# LPC55S66_cm33_core1 register map
Vendor: nxp.com; File version: 1.0
CPU: CM33 r2p0, little endian, no MPU, no FPU, VTOR, 3 interrupt priority bits
Registers are 32-bit, read-write, reset 0x0 unless marked. A register's access mark holds for its fields unless they carry their own. Offsets are from the block's base; [hi:lo] are bit positions; {n}, {i} and the like mark numbered series; 'fields as' and 'values as' point back to an identical list.

## IOCON — I/O pin configuration (IOCON)
Base 0x40001000
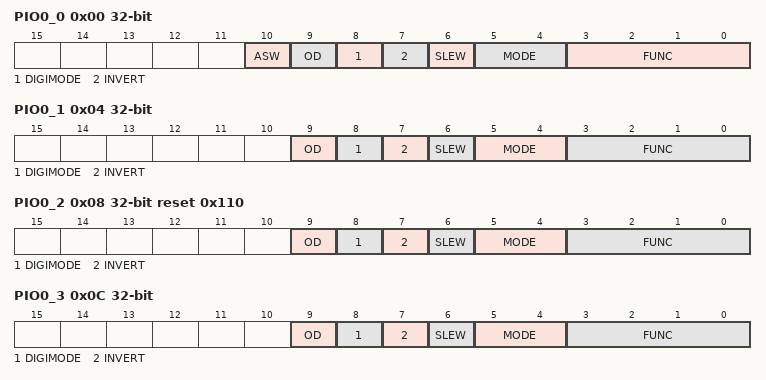
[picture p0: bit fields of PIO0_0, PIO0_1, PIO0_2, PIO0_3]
0x00 PIO0_0 — Digital I/O control for port 0 pins PIO0_0
  [10] ASW — Analog switch input control.
    0=For pins PIO0_9, PIO0_11, PIO0_12, PIO0_15, PIO0_18, PIO0_31, PIO1_0 and PIO1_9, analog switch is closed (enabled). For the other pins, analog switch is open (disabled).; 1=For all pins except PIO0_9, PIO0_11, PIO0_12, PIO0_15, PIO0_18, PIO0_31, PIO1_0 and PIO1_9 analog switch is closed (enabled)
  [9] OD — Controls open-drain mode.
    0=NORMAL (Normal. Normal push-pull output); 1=OPEN_DRAIN (Open-drain. Simulated open-drain output (high drive disabled).)
  [8] DIGIMODE — Select Digital mode.
    0=ANALOG (Disable digital mode. Digital input set to 0.); 1=DIGITAL (Enable Digital mode. Digital input is enabled.)
  [7] INVERT — Input polarity.
    0=DISABLED (Disabled. Input function is not inverted.); 1=ENABLED (Enabled. Input is function inverted.)
  [6] SLEW — Driver slew rate.
    0=STANDARD (Standard-mode, output slew rate is slower. More outputs can be switched simultaneously.); 1=FAST (Fast-mode, output slew rate is faster. Refer to the appropriate specific device data sheet for details.)
  [5:4] MODE — Selects function mode (on-chip pull-up/pull-down resistor control).
    0=INACTIVE (Inactive. Inactive (no pull-down/pull-up resistor enabled).); 1=PULL_DOWN (Pull-down. Pull-down resistor enabled.); 2=PULL_UP (Pull-up. Pull-up resistor enabled.); 3=REPEATER (Repeater. Repeater mode.)
  [3:0] FUNC — Selects pin function.
    {v}=ALT{v} (Alternative connection {v}.) (v=0..7)
0x04 PIO0_1 — Digital I/O control for port 0 pins PIO0_1
  [9] OD — Controls open-drain mode.
    values as PIO0_0.OD
  [8] DIGIMODE — Select Digital mode.
    values as PIO0_0.DIGIMODE
  [7] INVERT — Input polarity.
    values as PIO0_0.INVERT
  [6] SLEW — Driver slew rate.
    values as PIO0_0.SLEW
  [5:4] MODE — Selects function mode (on-chip pull-up/pull-down resistor control).
    values as PIO0_0.MODE
  [3:0] FUNC — Selects pin function.
    {v}=ALT{v} (Alternative connection {v}.) (v=0..7)
0x08 PIO0_2 reset 0x110 — Digital I/O control for port 0 pins PIO0_2
  fields as PIO0_1
0x0C PIO0_3 — Digital I/O control for port 0 pins PIO0_3
  fields as PIO0_1
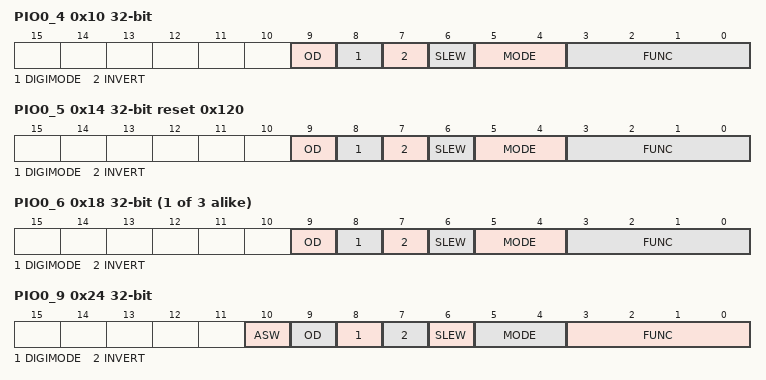
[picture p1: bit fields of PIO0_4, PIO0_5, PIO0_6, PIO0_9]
0x10 PIO0_4 — Digital I/O control for port 0 pins PIO0_4
  fields as PIO0_1
0x14 PIO0_5 reset 0x120 — Digital I/O control for port 0 pins PIO0_5
  fields as PIO0_1
{0x0+4i} PIO0_{i} (i=6..8) — Digital I/O control for port 0 pins PIO0_{i}
  fields as PIO0_1
0x24 PIO0_9 — Digital I/O control for port 0 pins PIO0_9
  fields as PIO0_0
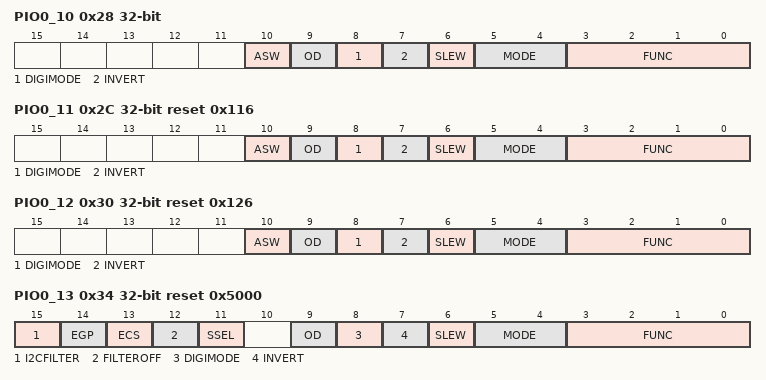
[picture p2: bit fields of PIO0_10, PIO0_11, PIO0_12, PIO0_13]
0x28 PIO0_10 — Digital I/O control for port 0 pins PIO0_10
  fields as PIO0_0
0x2C PIO0_11 reset 0x116 — Digital I/O control for port 0 pins PIO0_11
  fields as PIO0_0
0x30 PIO0_12 reset 0x126 — Digital I/O control for port 0 pins PIO0_12
  fields as PIO0_0
0x34 PIO0_13 reset 0x5000 — Digital I/O control for port 0 pins PIO0_13
  [15] I2CFILTER — Configures I2C features for standard mode, fast mode, and Fast Mode Plus operation and High-Speed mode operation.
    0=FAST_MODE (I2C 50 ns glitch filter enabled. Typically used for Standard-mode, Fast-mode and Fast-mode Plus I2C.); 1=STANDARD_MODE (I2C 10 ns glitch filter enabled. Typically used for High-speed mode I2C.)
  [14] EGP — Switch between GPIO mode and I2C mode.
    0=I2C_MODE; 1=GPIO_MODE
  [13] ECS — Pull-up current source enable in I2C mode.
    0=DISABLED (Disabled. IO is in open drain cell.); 1=ENABLED (Enabled. Pull resistor is conencted.)
  [12] FILTEROFF — Controls input glitch filter.
    0=ENABLED (Filter enabled.); 1=DISABLED (Filter disabled.)
  [11] SSEL — Supply Selection bit.
    0=SEL3V3 (3V3 Signaling in I2C Mode.); 1=SEL1V8 (1V8 Signaling in I2C Mode.)
  [9] OD — Controls open-drain mode in standard GPIO mode (EGP = 1). This bit has no effect in I2C mode (EGP=0).
    values as PIO0_0.OD
  [8] DIGIMODE — Select Digital mode.
    values as PIO0_0.DIGIMODE
  [7] INVERT — Input polarity.
    values as PIO0_0.INVERT
  [6] SLEW — Driver slew rate.
    values as PIO0_0.SLEW
  [5:4] MODE — Selects function mode (on-chip pull-up/pull-down resistor control).
    values as PIO0_0.MODE
  [3:0] FUNC — Selects pin function.
    {v}=ALT{v} (Alternative connection {v}.) (v=0..7)
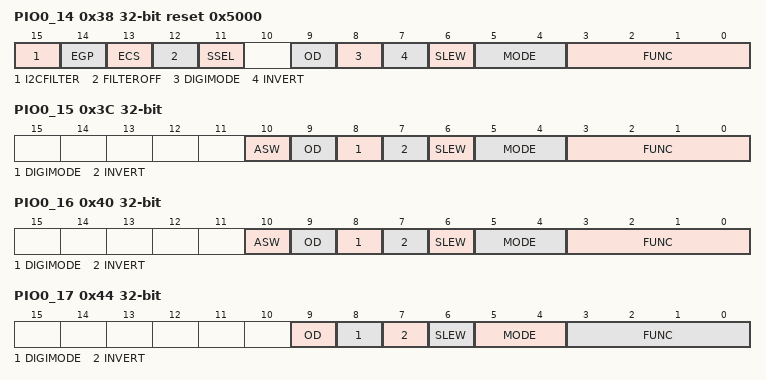
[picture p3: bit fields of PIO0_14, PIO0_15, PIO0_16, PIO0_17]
0x38 PIO0_14 reset 0x5000 — Digital I/O control for port 0 pins PIO0_14
  fields as PIO0_13
0x3C PIO0_15 — Digital I/O control for port 0 pins PIO0_15
  fields as PIO0_0
0x40 PIO0_16 — Digital I/O control for port 0 pins PIO0_16
  fields as PIO0_0
0x44 PIO0_17 — Digital I/O control for port 0 pins PIO0_17
  fields as PIO0_1
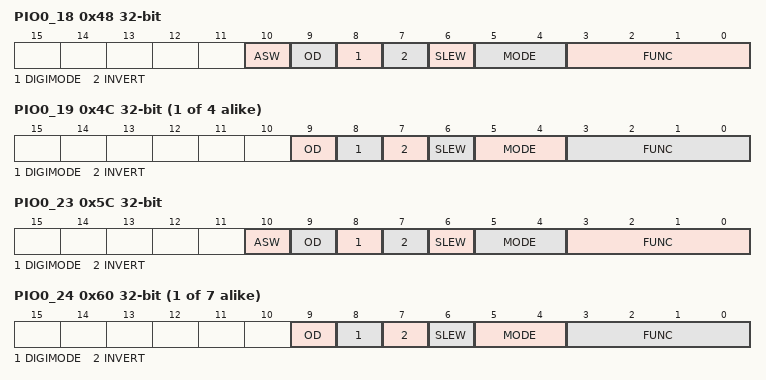
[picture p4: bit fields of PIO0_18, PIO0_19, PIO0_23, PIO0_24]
0x48 PIO0_18 — Digital I/O control for port 0 pins PIO0_18
  fields as PIO0_0
{0x0+4i} PIO0_{i} (i=19..22) — Digital I/O control for port 0 pins PIO0_{i}
  fields as PIO0_1
0x5C PIO0_23 — Digital I/O control for port 0 pins PIO0_23
  fields as PIO0_0
{0x0+4i} PIO0_{i} (i=24..30) — Digital I/O control for port 0 pins PIO0_{i}
  fields as PIO0_1
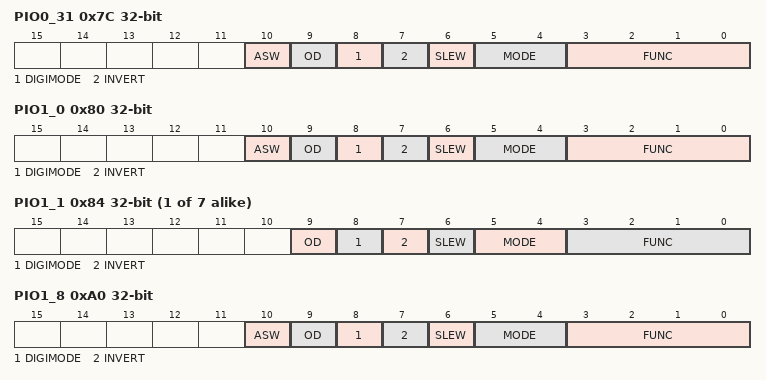
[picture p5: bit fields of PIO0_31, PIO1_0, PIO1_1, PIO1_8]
0x7C PIO0_31 — Digital I/O control for port 0 pins PIO0_31
  fields as PIO0_0
0x80 PIO1_0 — Digital I/O control for port 1 pins PIO1_0
  fields as PIO0_0
{0x80+4i} PIO1_{i} (i=1..7) — Digital I/O control for port 1 pins PIO1_{i}
  fields as PIO0_1
0xA0 PIO1_8 — Digital I/O control for port 1 pins PIO1_8
  fields as PIO0_0
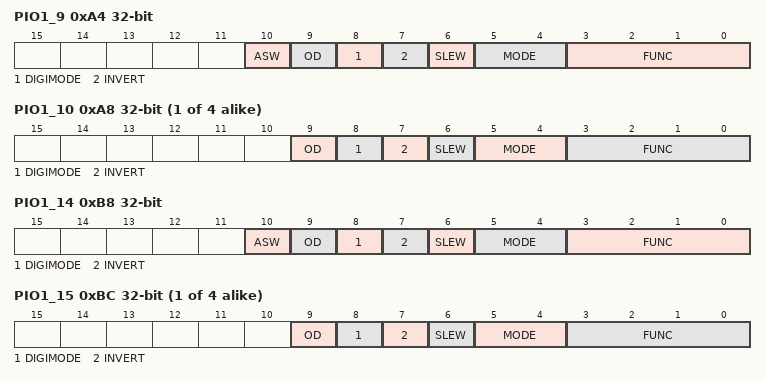
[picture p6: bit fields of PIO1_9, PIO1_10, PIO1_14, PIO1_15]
0xA4 PIO1_9 — Digital I/O control for port 1 pins PIO1_9
  fields as PIO0_0
{0x80+4i} PIO1_{i} (i=10..13) — Digital I/O control for port 1 pins PIO1_{i}
  fields as PIO0_1
0xB8 PIO1_14 — Digital I/O control for port 1 pins PIO1_14
  fields as PIO0_0
{0x80+4i} PIO1_{i} (i=15..18) — Digital I/O control for port 1 pins PIO1_{i}
  fields as PIO0_1
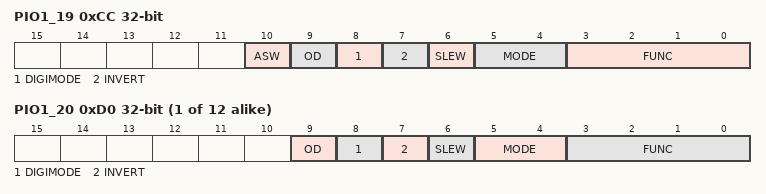
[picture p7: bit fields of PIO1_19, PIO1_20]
0xCC PIO1_19 — Digital I/O control for port 1 pins PIO1_19
  fields as PIO0_0
{0x80+4i} PIO1_{i} (i=20..31) — Digital I/O control for port 1 pins PIO1_{i}
  fields as PIO0_1
